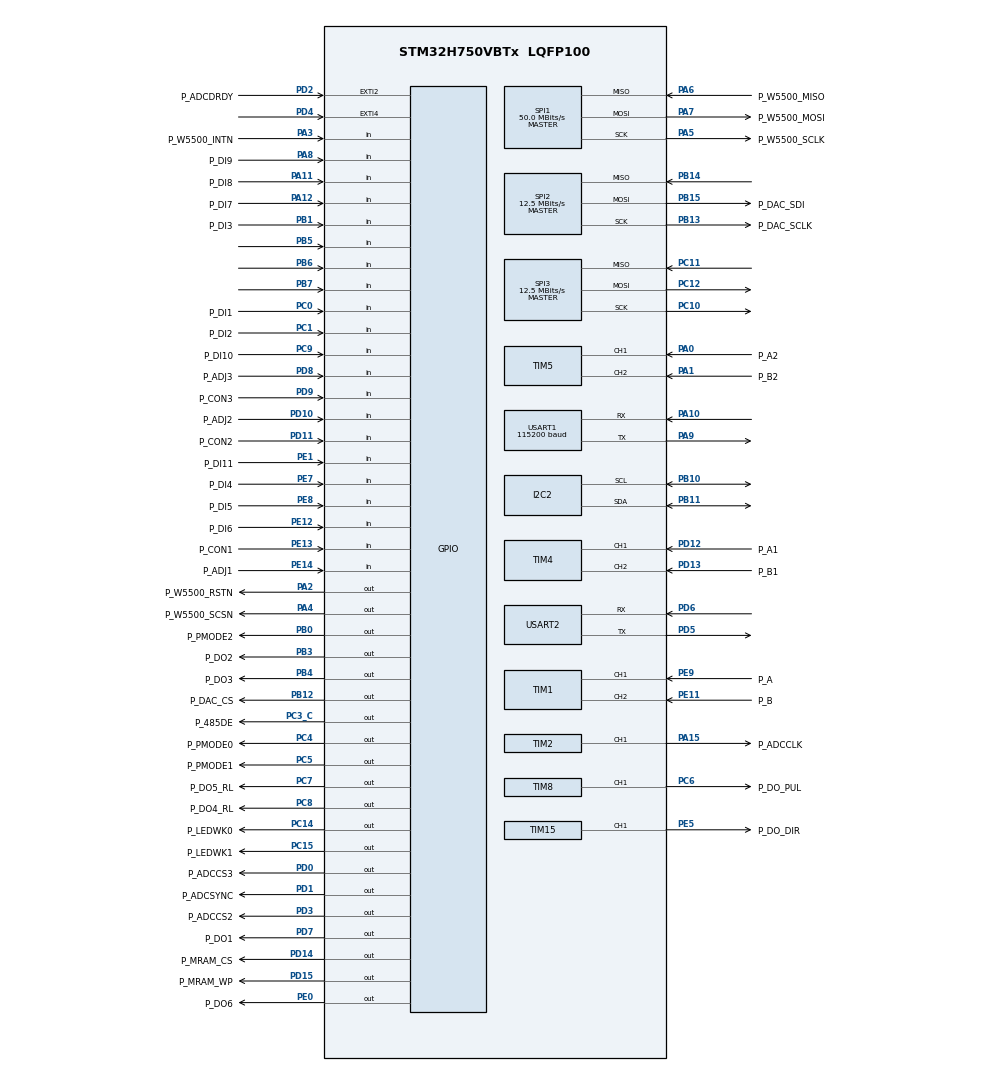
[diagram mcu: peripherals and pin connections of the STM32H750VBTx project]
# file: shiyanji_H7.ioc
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CORTEX_M7.CPU_DCache=Disabled
CORTEX_M7.CPU_ICache=Disabled
CORTEX_M7.MPU_Control=MPU_PRIVILEGED_DEFAULT
Dma.Request0=USART1_RX
Dma.Request1=USART1_TX
Dma.Request2=SPI3_RX
Dma.Request3=SPI3_TX
Dma.SPI3_RX.2.Direction=DMA_PERIPH_TO_MEMORY
Dma.SPI3_RX.2.EventEnable=DISABLE
Dma.SPI3_RX.2.FIFOMode=DMA_FIFOMODE_DISABLE
Dma.SPI3_RX.2.Instance=DMA1_Stream2
Dma.SPI3_RX.2.MemDataAlignment=DMA_MDATAALIGN_BYTE
Dma.SPI3_RX.2.MemInc=DMA_MINC_ENABLE
Dma.SPI3_RX.2.Mode=DMA_NORMAL
Dma.SPI3_RX.2.PeriphDataAlignment=DMA_PDATAALIGN_BYTE
Dma.SPI3_RX.2.PeriphInc=DMA_PINC_DISABLE
Dma.SPI3_RX.2.Polarity=HAL_DMAMUX_REQ_GEN_RISING
Dma.SPI3_RX.2.Priority=DMA_PRIORITY_LOW
Dma.SPI3_RX.2.RequestNumber=1
Dma.SPI3_RX.2.SignalID=NONE
Dma.SPI3_RX.2.SyncEnable=DISABLE
Dma.SPI3_RX.2.SyncPolarity=HAL_DMAMUX_SYNC_NO_EVENT
Dma.SPI3_RX.2.SyncRequestNumber=1
Dma.SPI3_RX.2.SyncSignalID=NONE
Dma.SPI3_TX.3.Direction=DMA_MEMORY_TO_PERIPH
Dma.SPI3_TX.3.EventEnable=DISABLE
Dma.SPI3_TX.3.FIFOMode=DMA_FIFOMODE_DISABLE
Dma.SPI3_TX.3.Instance=DMA1_Stream3
Dma.SPI3_TX.3.MemDataAlignment=DMA_MDATAALIGN_BYTE
Dma.SPI3_TX.3.MemInc=DMA_MINC_ENABLE
Dma.SPI3_TX.3.Mode=DMA_NORMAL
Dma.SPI3_TX.3.PeriphDataAlignment=DMA_PDATAALIGN_BYTE
Dma.SPI3_TX.3.PeriphInc=DMA_PINC_DISABLE
Dma.SPI3_TX.3.Polarity=HAL_DMAMUX_REQ_GEN_RISING
Dma.SPI3_TX.3.Priority=DMA_PRIORITY_LOW
Dma.SPI3_TX.3.RequestNumber=1
Dma.SPI3_TX.3.SignalID=NONE
Dma.SPI3_TX.3.SyncEnable=DISABLE
Dma.SPI3_TX.3.SyncPolarity=HAL_DMAMUX_SYNC_NO_EVENT
Dma.SPI3_TX.3.SyncRequestNumber=1
Dma.SPI3_TX.3.SyncSignalID=NONE
Dma.USART1_RX.0.Direction=DMA_PERIPH_TO_MEMORY
Dma.USART1_RX.0.EventEnable=DISABLE
Dma.USART1_RX.0.FIFOMode=DMA_FIFOMODE_DISABLE
Dma.USART1_RX.0.Instance=DMA1_Stream0
Dma.USART1_RX.0.MemDataAlignment=DMA_MDATAALIGN_BYTE
Dma.USART1_RX.0.MemInc=DMA_MINC_ENABLE
Dma.USART1_RX.0.Mode=DMA_NORMAL
Dma.USART1_RX.0.PeriphDataAlignment=DMA_PDATAALIGN_BYTE
Dma.USART1_RX.0.PeriphInc=DMA_PINC_DISABLE
Dma.USART1_RX.0.Polarity=HAL_DMAMUX_REQ_GEN_RISING
Dma.USART1_RX.0.Priority=DMA_PRIORITY_LOW
Dma.USART1_RX.0.RequestNumber=1
Dma.USART1_RX.0.SignalID=NONE
Dma.USART1_RX.0.SyncEnable=DISABLE
Dma.USART1_RX.0.SyncPolarity=HAL_DMAMUX_SYNC_NO_EVENT
Dma.USART1_RX.0.SyncRequestNumber=1
Dma.USART1_RX.0.SyncSignalID=NONE
Dma.USART1_TX.1.Direction=DMA_MEMORY_TO_PERIPH
Dma.USART1_TX.1.EventEnable=DISABLE
Dma.USART1_TX.1.FIFOMode=DMA_FIFOMODE_DISABLE
Dma.USART1_TX.1.Instance=DMA1_Stream1
Dma.USART1_TX.1.MemDataAlignment=DMA_MDATAALIGN_BYTE
Dma.USART1_TX.1.MemInc=DMA_MINC_ENABLE
Dma.USART1_TX.1.Mode=DMA_NORMAL
Dma.USART1_TX.1.PeriphDataAlignment=DMA_PDATAALIGN_BYTE
Dma.USART1_TX.1.PeriphInc=DMA_PINC_DISABLE
Dma.USART1_TX.1.Polarity=HAL_DMAMUX_REQ_GEN_RISING
Dma.USART1_TX.1.Priority=DMA_PRIORITY_LOW
Dma.USART1_TX.1.RequestNumber=1
Dma.USART1_TX.1.SignalID=NONE
Dma.USART1_TX.1.SyncEnable=DISABLE
Dma.USART1_TX.1.SyncPolarity=HAL_DMAMUX_SYNC_NO_EVENT
Dma.USART1_TX.1.SyncRequestNumber=1
Dma.USART1_TX.1.SyncSignalID=NONE
I2C2.Timing=0x10C0ECFF
Mcu.Family=STM32H7
Mcu.Name=STM32H750VBTx
Mcu.Package=LQFP100
NVIC.DMA1_Stream0_IRQn=true\:0\:0\:false\:false\:true\:false\:true\:true
NVIC.DMA1_Stream1_IRQn=true\:0\:0\:false\:false\:true\:false\:true\:true
NVIC.DMA1_Stream2_IRQn=true\:0\:0\:false\:false\:true\:false\:true\:true
NVIC.DMA1_Stream3_IRQn=true\:0\:0\:false\:false\:true\:false\:true\:true
NVIC.EXTI4_IRQn=true\:0\:0\:false\:false\:true\:true\:true\:true
NVIC.PriorityGroup=NVIC_PRIORITYGROUP_4
NVIC.SPI3_IRQn=true\:0\:0\:false\:false\:true\:false\:true\:true
NVIC.TIM16_IRQn=true\:5\:0\:true\:false\:true\:true\:true\:true
NVIC.TIM17_IRQn=true\:5\:0\:true\:false\:true\:true\:true\:true
NVIC.TIM7_IRQn=true\:15\:0\:true\:false\:true\:false\:true\:true
NVIC.TIM8_CC_IRQn=true\:0\:0\:false\:false\:true\:true\:true\:true
NVIC.TimeBase=TIM7_IRQn
NVIC.TimeBaseIP=TIM7
NVIC.USART1_IRQn=true\:0\:0\:false\:false\:true\:true\:true\:true
NVIC.USART2_IRQn=true\:0\:0\:false\:false\:true\:true\:true\:true
PA0.GPIO_Label=P_A2
PA0.Signal=S_TIM5_CH1
PA1.GPIO_Label=P_B2
PA1.Signal=S_TIM5_CH2
PA10.Mode=Asynchronous
PA10.Signal=USART1_RX
PA11.GPIO_Label=P_DI8
PA11.Signal=GPIO_Input
PA12.GPIO_Label=P_DI7
PA12.Signal=GPIO_Input
PA13\ (JTMS/SWDIO).Mode=Serial_Wire
PA13\ (JTMS/SWDIO).Signal=DEBUG_JTMS-SWDIO
PA14\ (JTCK/SWCLK).Mode=Serial_Wire
PA14\ (JTCK/SWCLK).Signal=DEBUG_JTCK-SWCLK
PA15\ (JTDI).GPIO_Label=P_ADCCLK
PA15\ (JTDI).Signal=S_TIM2_CH1_ETR
PA2.GPIO_Label=P_W5500_RSTN
PA2.Signal=GPIO_Output
PA3.GPIO_Label=P_W5500_INTN
PA3.Signal=GPIO_Input
PA4.GPIO_Label=P_W5500_SCSN
PA4.Signal=GPIO_Output
PA5.GPIO_Label=P_W5500_SCLK
PA5.GPIO_Speed=GPIO_SPEED_FREQ_VERY_HIGH
PA5.Mode=Full_Duplex_Master
PA5.Signal=SPI1_SCK
PA6.GPIO_Label=P_W5500_MISO
PA6.GPIO_Speed=GPIO_SPEED_FREQ_VERY_HIGH
PA6.Mode=Full_Duplex_Master
PA6.Signal=SPI1_MISO
PA7.GPIO_Label=P_W5500_MOSI
PA7.GPIO_Speed=GPIO_SPEED_FREQ_VERY_HIGH
PA7.Mode=Full_Duplex_Master
PA7.Signal=SPI1_MOSI
PA8.GPIO_Label=P_DI9
PA8.Signal=GPIO_Input
PA9.Mode=Asynchronous
PA9.Signal=USART1_TX
PB0.GPIO_Label=P_PMODE2
PB0.Signal=GPIO_Output
PB1.GPIO_Label=P_DI3
PB1.Signal=GPIO_Input
PB10.GPIO_Speed=GPIO_SPEED_FREQ_HIGH
PB10.Mode=I2C
PB10.Signal=I2C2_SCL
PB11.GPIO_Speed=GPIO_SPEED_FREQ_HIGH
PB11.Mode=I2C
PB11.Signal=I2C2_SDA
PB12.GPIO_Label=P_DAC_CS
PB12.GPIO_Speed=GPIO_SPEED_FREQ_HIGH
PB12.PinState=GPIO_PIN_SET
PB12.Signal=GPIO_Output
PB13.GPIO_Label=P_DAC_SCLK
PB13.Mode=Full_Duplex_Master
PB13.Signal=SPI2_SCK
PB14.Mode=Full_Duplex_Master
PB14.Signal=SPI2_MISO
PB15.GPIO_Label=P_DAC_SDI
PB15.Mode=Full_Duplex_Master
PB15.Signal=SPI2_MOSI
PB3\ (JTDO/TRACESWO).GPIO_Label=P_DO2
PB3\ (JTDO/TRACESWO).Signal=GPIO_Output
PB4\ (NJTRST).GPIO_Label=P_DO3
PB4\ (NJTRST).Signal=GPIO_Output
PB5.Signal=GPIO_Input
PB6.Signal=GPIO_Input
PB7.Signal=GPIO_Input
PC0.GPIO_Label=P_DI1
PC0.Signal=GPIO_Input
PC1.GPIO_Label=P_DI2
PC1.Signal=GPIO_Input
PC10.Mode=Full_Duplex_Master
PC10.Signal=SPI3_SCK
PC11.Mode=Full_Duplex_Master
PC11.Signal=SPI3_MISO
PC12.Mode=Full_Duplex_Master
PC12.Signal=SPI3_MOSI
PC14-OSC32_IN\ (OSC32_IN).GPIO_Label=P_LEDWK0
PC14-OSC32_IN\ (OSC32_IN).Signal=GPIO_Output
PC15-OSC32_OUT\ (OSC32_OUT).GPIO_Label=P_LEDWK1
PC15-OSC32_OUT\ (OSC32_OUT).Signal=GPIO_Output
PC3_C.GPIO_Label=P_485DE
PC3_C.Signal=GPIO_Output
PC4.GPIO_Label=P_PMODE0
PC4.Signal=GPIO_Output
PC5.GPIO_Label=P_PMODE1
PC5.GPIO_PuPd=GPIO_PULLUP
PC5.PinState=GPIO_PIN_SET
PC5.Signal=GPIO_Output
PC6.GPIO_Label=P_DO_PUL
PC6.GPIO_Speed=GPIO_SPEED_FREQ_VERY_HIGH
PC6.Signal=S_TIM8_CH1
PC7.GPIO_Label=P_DO5_RL
PC7.Signal=GPIO_Output
PC8.GPIO_Label=P_DO4_RL
PC8.Signal=GPIO_Output
PC9.GPIO_Label=P_DI10
PC9.Signal=GPIO_Input
PD0.GPIO_Label=P_ADCCS3
PD0.GPIO_Speed=GPIO_SPEED_FREQ_HIGH
PD0.PinState=GPIO_PIN_SET
PD0.Signal=GPIO_Output
PD1.GPIO_Label=P_ADCSYNC
PD1.Signal=GPIO_Output
PD10.GPIO_Label=P_ADJ2
PD10.Signal=GPIO_Input
PD11.GPIO_Label=P_CON2
PD11.Signal=GPIO_Input
PD12.GPIO_Label=P_A1
PD12.Signal=S_TIM4_CH1
PD13.GPIO_Label=P_B1
PD13.Signal=S_TIM4_CH2
PD14.GPIO_Label=P_MRAM_CS
PD14.GPIO_Speed=GPIO_SPEED_FREQ_HIGH
PD14.PinState=GPIO_PIN_SET
PD14.Signal=GPIO_Output
PD15.GPIO_Label=P_MRAM_WP
PD15.GPIO_Speed=GPIO_SPEED_FREQ_HIGH
PD15.PinState=GPIO_PIN_SET
PD15.Signal=GPIO_Output
PD2.GPIO_Label=P_ADCDRDY
PD2.GPIO_ModeDefaultEXTI=GPIO_MODE_IT_FALLING
PD2.Signal=GPXTI2
PD3.GPIO_Label=P_ADCCS2
PD3.GPIO_Speed=GPIO_SPEED_FREQ_HIGH
PD3.PinState=GPIO_PIN_SET
PD3.Signal=GPIO_Output
PD4.GPIO_ModeDefaultEXTI=GPIO_MODE_IT_FALLING
PD4.GPIO_PuPd=GPIO_PULLUP
PD4.Signal=GPXTI4
PD5.Mode=Asynchronous
PD5.Signal=USART2_TX
PD6.Mode=Asynchronous
PD6.Signal=USART2_RX
PD7.GPIO_Label=P_DO1
PD7.Signal=GPIO_Output
PD8.GPIO_Label=P_ADJ3
PD8.Signal=GPIO_Input
PD9.GPIO_Label=P_CON3
PD9.Signal=GPIO_Input
PE0.GPIO_Label=P_DO6
PE0.Signal=GPIO_Output
PE1.GPIO_Label=P_DI11
PE1.GPIO_PuPd=GPIO_PULLUP
PE1.Signal=GPIO_Input
PE11.GPIO_Label=P_B
PE11.Signal=S_TIM1_CH2
PE12.GPIO_Label=P_DI6
PE12.Signal=GPIO_Input
PE13.GPIO_Label=P_CON1
PE13.Signal=GPIO_Input
PE14.GPIO_Label=P_ADJ1
PE14.Signal=GPIO_Input
PE5.GPIO_Label=P_DO_DIR
PE5.GPIO_Speed=GPIO_SPEED_FREQ_VERY_HIGH
PE5.Signal=S_TIM15_CH1
PE7.GPIO_Label=P_DI4
PE7.Signal=GPIO_Input
PE8.GPIO_Label=P_DI5
PE8.Signal=GPIO_Input
PE9.GPIO_Label=P_A
PE9.Signal=S_TIM1_CH1
PH0-OSC_IN\ (PH0).Mode=HSE-External-Oscillator
PH0-OSC_IN\ (PH0).Signal=RCC_OSC_IN
PH1-OSC_OUT\ (PH1).Mode=HSE-External-Oscillator
PH1-OSC_OUT\ (PH1).Signal=RCC_OSC_OUT
ProjectManager.HeapSize=0x1000
ProjectManager.StackSize=0x1000
ProjectManager.TargetToolchain=MDK-ARM V5
RCC.ADCFreq_Value=16125000
RCC.APB1Freq_Value=100000000
RCC.APB2Freq_Value=100000000
RCC.APB3Freq_Value=100000000
RCC.APB4Freq_Value=100000000
RCC.CortexFreq_Value=400000000
RCC.D1PPRE=RCC_APB3_DIV2
RCC.D2PPRE1=RCC_APB1_DIV2
RCC.D2PPRE2=RCC_APB2_DIV2
RCC.D3PPRE=RCC_APB4_DIV2
RCC.DIVM1=1
RCC.DIVN1=100
RCC.DIVQ1=4
RCC.HCLKFreq_Value=200000000
RCC.HPRE=RCC_HCLK_DIV2
RCC.HSE_VALUE=8000000
RCC.PLL2FRACN=0
RCC.PLL3FRACN=0
RCC.PLLFRACN=0
RCC.PLLSourceVirtual=RCC_PLLSOURCE_HSE
RCC.PWR_Regulator_Voltage_Scale=PWR_REGULATOR_VOLTAGE_SCALE0
RCC.ProductRev=revV
RCC.SYSCLKFreq_VALUE=400000000
RCC.SYSCLKSource=RCC_SYSCLKSOURCE_PLLCLK
RCC.SupplySource=PWR_LDO_SUPPLY
RCC.USBFreq_Value=200000000
SH.S_TIM15_CH1.0=TIM15_CH1,PWM Generation1 CH1
SH.S_TIM1_CH1.0=TIM1_CH1,Encoder_Interface
SH.S_TIM1_CH2.0=TIM1_CH2,Encoder_Interface
SH.S_TIM2_CH1_ETR.0=TIM2_CH1,PWM Generation1 CH1
SH.S_TIM4_CH1.0=TIM4_CH1,Encoder_Interface
SH.S_TIM4_CH2.0=TIM4_CH2,Encoder_Interface
SH.S_TIM5_CH1.0=TIM5_CH1,Encoder_Interface
SH.S_TIM5_CH2.0=TIM5_CH2,Encoder_Interface
SH.S_TIM8_CH1.0=TIM8_CH1,PWM Generation1 CH1
SPI1.BaudRatePrescaler=SPI_BAUDRATEPRESCALER_4
SPI1.CalculateBaudRate=50.0 MBits/s
SPI1.DataSize=SPI_DATASIZE_8BIT
SPI1.Direction=SPI_DIRECTION_2LINES
SPI1.Mode=SPI_MODE_MASTER
SPI1.NSSPMode=SPI_NSS_PULSE_DISABLE
SPI1.VirtualType=VM_MASTER
SPI2.BaudRatePrescaler=SPI_BAUDRATEPRESCALER_16
SPI2.CalculateBaudRate=12.5 MBits/s
SPI2.DataSize=SPI_DATASIZE_8BIT
SPI2.Direction=SPI_DIRECTION_2LINES
SPI2.Mode=SPI_MODE_MASTER
SPI2.VirtualType=VM_MASTER
SPI3.BaudRatePrescaler=SPI_BAUDRATEPRESCALER_16
SPI3.CalculateBaudRate=12.5 MBits/s
SPI3.DataSize=SPI_DATASIZE_8BIT
SPI3.Direction=SPI_DIRECTION_2LINES
SPI3.Mode=SPI_MODE_MASTER
SPI3.VirtualType=VM_MASTER
TIM1.EncoderMode=TIM_ENCODERMODE_TI12
TIM13.AutoReloadPreload=TIM_AUTORELOAD_PRELOAD_ENABLE
TIM13.Prescaler=200-1
TIM14.AutoReloadPreload=TIM_AUTORELOAD_PRELOAD_ENABLE
TIM14.Period=200-1
TIM15.Channel-PWM\ Generation1\ CH1=TIM_CHANNEL_1
TIM15.Period=10000-1
TIM15.Pulse-PWM\ Generation1\ CH1=5000
TIM16.Period=100-1
TIM16.Prescaler=1000-1
TIM17.Period=80-1
TIM17.Prescaler=1000-1
TIM2.Channel-PWM\ Generation1\ CH1=TIM_CHANNEL_1
TIM2.Period=38-1
TIM2.Pulse-PWM\ Generation1\ CH1=19
TIM4.EncoderMode=TIM_ENCODERMODE_TI12
TIM6.AutoReloadPreload=TIM_AUTORELOAD_PRELOAD_ENABLE
TIM6.Period=50000-1
TIM6.Prescaler=200-1
TIM8.Channel-PWM\ Generation1\ CH1=TIM_CHANNEL_1
TIM8.Period=10000-1
TIM8.Pulse-PWM\ Generation1\ CH1=5000
USART1.BaudRate=115200
USART1.VirtualMode-Asynchronous=VM_ASYNC
USART2.VirtualMode-Asynchronous=VM_ASYNC
VP_MEMORYMAP_VS_MEMORYMAP.Mode=CurAppReg
VP_SYS_VS_tim7.Mode=TIM7
VP_TIM13_VS_ClockSourceINT.Mode=Enable_Timer
VP_TIM14_VS_ClockSourceINT.Mode=Enable_Timer
VP_TIM15_VS_ClockSourceINT.Mode=Internal
VP_TIM16_VS_ClockSourceINT.Mode=Enable_Timer
VP_TIM17_VS_ClockSourceINT.Mode=Enable_Timer
VP_TIM2_VS_ClockSourceINT.Mode=Internal
VP_TIM6_VS_ClockSourceINT.Mode=Enable_Timer
VP_TIM8_VS_ClockSourceINT.Mode=Internal
board=custom

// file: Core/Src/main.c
/* USER CODE BEGIN Header */
/**
  ******************************************************************************
  * @file           : main.c
  * @brief          : Main program body
  ******************************************************************************
  * @attention
  *
  * Copyright (c) 2026 STMicroelectronics.
  * All rights reserved.
  *
  * This software is licensed under terms that can be found in the LICENSE file
  * in the root directory of this software component.
  * If no LICENSE file comes with this software, it is provided AS-IS.
  *
  ******************************************************************************
  */
/* USER CODE END Header */
#include "main.h"
#include "dma.h"
#include "i2c.h"
#include "spi.h"
#include "tim.h"
#include "usart.h"
#include "gpio.h"

/* USER CODE BEGIN Includes */
#include "user.h"
#include "filter.h"
/* USER CODE END Includes */

/* USER CODE BEGIN PV */
static SlidingAvgFilter voltage_filter_ch0;
static SlidingAvgFilter voltage_filter_ch1;
static volatile float g_voltage_filtered_ch0 = 0.0f;
static volatile uint8_t g_voltage_filtered_valid_ch0 = 0u;
/* USER CODE END PV */

void SystemClock_Config(void);
static void MPU_Config(void);
/* USER CODE BEGIN PFP */

#include <stdio.h>
struct __FILE
{
  int handle;
};
FILE __stdout;
int fputc(int ch, FILE *f)
{
  HAL_UART_Transmit(&huart1, (uint8_t *)&ch, 1, 50);
  return ch;
}
/* USER CODE END PFP */

/* USER CODE BEGIN 0 */
bool cs5552_ready = false;
uint32_t ch0_valid_sample_count = 0;
uint32_t ch0_valid_sample_tick = 0;
uint32_t ch0_invalid_sample_count = 0;
/* USER CODE END 0 */

int main(void)
{

  /* MPU Configuration--------------------------------------------------------*/
  MPU_Config();

  /* MCU Configuration--------------------------------------------------------*/

  /* Reset of all peripherals, Initializes the Flash interface and the Systick. */
  HAL_Init();

  /* Configure the system clock */
  SystemClock_Config();

  /* Initialize all configured peripherals */
  MX_GPIO_Init();
  MX_DMA_Init();
  MX_TIM1_Init();
  MX_TIM2_Init();
  MX_TIM4_Init();
  MX_TIM5_Init();
  MX_TIM8_Init();
  MX_I2C2_Init();
  MX_SPI2_Init();
  MX_TIM15_Init();
  MX_USART1_UART_Init();
  MX_USART2_UART_Init();
  MX_TIM6_Init();
  MX_TIM16_Init();
  MX_TIM17_Init();
  MX_SPI1_Init();
  MX_TIM14_Init();
  MX_TIM13_Init();
  MX_SPI3_Init();
  /* USER CODE BEGIN 2 */
  CoreDebug->DEMCR |= CoreDebug_DEMCR_TRCENA_Msk;
  DWT->CYCCNT = 0;
  DWT->CTRL |= DWT_CTRL_CYCCNTENA_Msk;

  printf("System Boot\r\n");

  cs5552_ready = false;

  CS5552_SelectChip(CS5552_CHIP_0);
  if (CS5552_Init()) {
    printf("CS5552-0 Init OK\r\n");
    CS5552_StartContConv(CS5552_CONFIG_IDX_CH1);
    cs5552_ready = true;
  } else {
    printf("CS5552-0 Init Fail!\r\n");
  }

  CS5552_SelectChip(CS5552_CHIP_1);
  if (CS5552_Init()) {
    printf("CS5552-1 Init OK\r\n");
    CS5552_StartContConv(CS5552_CONFIG_IDX_CH0);
  } else {
    printf("CS5552-1 Init Fail!\r\n");
  }

  Filter_Init(&voltage_filter_ch0);
  Filter_Init(&voltage_filter_ch1);

  if (HAL_TIM_Base_Start_IT(&htim17) != HAL_OK) {
    Error_Handler();
  }
  /* USER CODE END 2 */

  /* Infinite loop */
  while (1)
  {

    /* USER CODE BEGIN 3 */
    static uint32_t voltage_print_tick = 0;

    if (g_voltage_filtered_valid_ch0 && (HAL_GetTick() - voltage_print_tick >= 10u)) {
      voltage_print_tick = HAL_GetTick();
      printf("%.6f\r\n", g_voltage_filtered_ch0);
    }

    if (HAL_GetTick() - ch0_valid_sample_tick >= 1000u) {
      printf("rate is %lu invalid %lu-----------------------\r\n\r\n\r\n\r\n",
             ch0_valid_sample_count, ch0_invalid_sample_count);

      ch0_valid_sample_count = 0;
      ch0_invalid_sample_count = 0;
      ch0_valid_sample_tick = HAL_GetTick();
    }
  }
  /* USER CODE END 3 */
}

void SystemClock_Config(void)
{
  RCC_OscInitTypeDef RCC_OscInitStruct = {0};
  RCC_ClkInitTypeDef RCC_ClkInitStruct = {0};

  HAL_PWREx_ConfigSupply(PWR_LDO_SUPPLY);

  __HAL_PWR_VOLTAGESCALING_CONFIG(PWR_REGULATOR_VOLTAGE_SCALE0);

  while(!__HAL_PWR_GET_FLAG(PWR_FLAG_VOSRDY)) {}

  RCC_OscInitStruct.OscillatorType = RCC_OSCILLATORTYPE_HSE;
  RCC_OscInitStruct.HSEState = RCC_HSE_ON;
  RCC_OscInitStruct.PLL.PLLState = RCC_PLL_ON;
  RCC_OscInitStruct.PLL.PLLSource = RCC_PLLSOURCE_HSE;
  RCC_OscInitStruct.PLL.PLLM = 1;
  RCC_OscInitStruct.PLL.PLLN = 100;
  RCC_OscInitStruct.PLL.PLLP = 2;
  RCC_OscInitStruct.PLL.PLLQ = 4;
  RCC_OscInitStruct.PLL.PLLR = 2;
  RCC_OscInitStruct.PLL.PLLRGE = RCC_PLL1VCIRANGE_3;
  RCC_OscInitStruct.PLL.PLLVCOSEL = RCC_PLL1VCOWIDE;
  RCC_OscInitStruct.PLL.PLLFRACN = 0;
  if (HAL_RCC_OscConfig(&RCC_OscInitStruct) != HAL_OK)
  {
    Error_Handler();
  }

  RCC_ClkInitStruct.ClockType = RCC_CLOCKTYPE_HCLK|RCC_CLOCKTYPE_SYSCLK
                              |RCC_CLOCKTYPE_PCLK1|RCC_CLOCKTYPE_PCLK2
                              |RCC_CLOCKTYPE_D3PCLK1|RCC_CLOCKTYPE_D1PCLK1;
  RCC_ClkInitStruct.SYSCLKSource = RCC_SYSCLKSOURCE_PLLCLK;
  RCC_ClkInitStruct.SYSCLKDivider = RCC_SYSCLK_DIV1;
  RCC_ClkInitStruct.AHBCLKDivider = RCC_HCLK_DIV2;
  RCC_ClkInitStruct.APB3CLKDivider = RCC_APB3_DIV2;
  RCC_ClkInitStruct.APB1CLKDivider = RCC_APB1_DIV2;
  RCC_ClkInitStruct.APB2CLKDivider = RCC_APB2_DIV2;
  RCC_ClkInitStruct.APB4CLKDivider = RCC_APB4_DIV2;

  if (HAL_RCC_ClockConfig(&RCC_ClkInitStruct, FLASH_LATENCY_2) != HAL_OK)
  {
    Error_Handler();
  }
}

/* USER CODE BEGIN 4 */
void HAL_TIM_PeriodElapsedCallback(TIM_HandleTypeDef *htim)
{
  if (htim->Instance == TIM7)
  {
    HAL_IncTick();
  }
  else if (htim->Instance == TIM17)
  {
    uint32_t adc_raw;
    int32_t adc_code;

    if (!cs5552_ready) {
      return;
    }

    CS5552_SelectChip(CS5552_CHIP_0);
    if (CS5552_ReadReg(REG_CONV_DATA, &adc_raw)) {
      uint32_t top3 = (adc_raw >> 29) & 0x7u;
      if (CS5552_ParseConvData(adc_raw, 1u, &adc_code, NULL) &&
          !(top3 == 0x2u || top3 == 0x3u || top3 == 0x4u || top3 == 0x5u ||
            adc_raw == 0xFFFFFFFFu || adc_raw == 0xFFFFFFFEu || adc_raw == 0x0u)) {
        ch0_valid_sample_count++;
        {
          int32_t adc_24bit = adc_code >> 6;
          float voltage_mv = CS5552_ConvertToVoltage(adc_24bit, 64);
          float voltage_filtered = Filter_Update(&voltage_filter_ch0, voltage_mv);
          g_voltage_filtered_ch0 = voltage_filtered * 1000;
          g_voltage_filtered_valid_ch0 = 1u;
        }
      } else {
        ch0_invalid_sample_count++;
        // printf("CH0 data Parse Error!\r\n");
      }
    } else {
      // printf("CH0 Read Error!\r\n");
    }
  }
}
/* USER CODE END 4 */

 /* MPU Configuration */

void MPU_Config(void)
{
  HAL_MPU_Disable();
  HAL_MPU_Enable(MPU_PRIVILEGED_DEFAULT);
}

void Error_Handler(void)
{
  __disable_irq();
  while (1)
  {
  }
}
